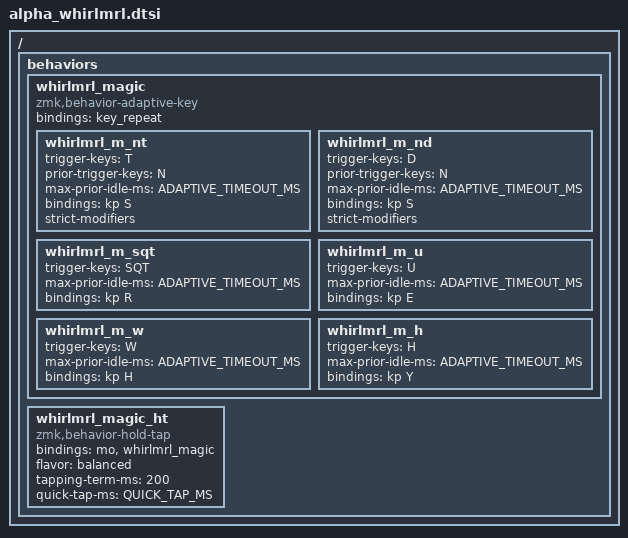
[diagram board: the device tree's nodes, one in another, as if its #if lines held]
/* Whirl-MRL — left-hand space, right-thumb repeat-magic. Inactive by default. */

/* >>> generated adaptive swaps (do not edit — run ./scripts/generate) >>> */
#include "../generated/alpha_whirlmrl.dtsi"
/* <<< end generated adaptive swaps <<< */

/* Repeat-magic thumb (hand-written; not a two-letter swap). */
#if WHIRLMRL_ADAPTIVE
ZMK_ADAPTIVE_KEY(whirlmrl_magic, bindings = <&key_repeat>;
    whirlmrl_m_nt  { trigger-keys = <T>; prior-trigger-keys = <N>; max-prior-idle-ms = <ADAPTIVE_TIMEOUT_MS>; bindings = <&kp S>; strict-modifiers; };
    whirlmrl_m_nd  { trigger-keys = <D>; prior-trigger-keys = <N>; max-prior-idle-ms = <ADAPTIVE_TIMEOUT_MS>; bindings = <&kp S>; strict-modifiers; };
    whirlmrl_m_sqt { trigger-keys = <SQT>; max-prior-idle-ms = <ADAPTIVE_TIMEOUT_MS>; bindings = <&kp R>; };
    whirlmrl_m_u   { trigger-keys = <U>;   max-prior-idle-ms = <ADAPTIVE_TIMEOUT_MS>; bindings = <&kp E>; };
    whirlmrl_m_w   { trigger-keys = <W>;   max-prior-idle-ms = <ADAPTIVE_TIMEOUT_MS>; bindings = <&kp H>; };
    whirlmrl_m_h   { trigger-keys = <H>;   max-prior-idle-ms = <ADAPTIVE_TIMEOUT_MS>; bindings = <&kp Y>; };
)
ZMK_HOLD_TAP(whirlmrl_magic_ht, bindings = <&mo>, <&whirlmrl_magic>;
             flavor = "balanced"; tapping-term-ms = <200>;
             quick-tap-ms = <QUICK_TAP_MS>;)
#define WHIRLMRL_MAGIC &whirlmrl_magic_ht LAYER_Num 0
#endif

#ifndef WHIRLMRL_C
#define WHIRLMRL_C &kp C
#endif
#ifndef WHIRLMRL_D
#define WHIRLMRL_D &kp D
#endif
#ifndef WHIRLMRL_F
#define WHIRLMRL_F &kp F
#endif
#ifndef WHIRLMRL_G
#define WHIRLMRL_G &kp G
#endif
#ifndef WHIRLMRL_H
#define WHIRLMRL_H &hml LSHFT H
#endif
#ifndef WHIRLMRL_L
#define WHIRLMRL_L &kp L
#endif
#ifndef WHIRLMRL_M
#define WHIRLMRL_M &kp M
#endif
#ifndef WHIRLMRL_P
#define WHIRLMRL_P &kp P
#endif
#ifndef WHIRLMRL_S
#define WHIRLMRL_S &hml LALT S
#endif
#ifndef WHIRLMRL_T
#define WHIRLMRL_T &hml LCTRL T
#endif
#ifndef WHIRLMRL_W
#define WHIRLMRL_W &kp W
#endif
#ifndef WHIRLMRL_MAGIC
#define WHIRLMRL_MAGIC &num_repeat LAYER_Num 0
#endif

ZMK_BASE_LAYER(WhirlMrl,
//╭──────────┬──────────┬──────────┬──────────┬──────────╮   ╭──────────┬──────────┬──────────┬──────────┬──────────╮
    &kp B      WHIRLMRL_C WHIRLMRL_D WHIRLMRL_W &kp K      ,  &sqt_dqt   WHIRLMRL_L &kp U      &kp O      &kp J      ,
//├──────────┼──────────┼──────────┼──────────┼──────────┤   ├──────────┼──────────┼──────────┼──────────┼──────────┤
   &hml LGUI N WHIRLMRL_S WHIRLMRL_T WHIRLMRL_H &kp Y , WHIRLMRL_M &hmr RSHFT R &hmr RCTRL E &hmr RALT A &hmr RGUI I ,
//├──────────┼──────────┼──────────┼──────────┼──────────┤   ├──────────┼──────────┼──────────┼──────────┼──────────┤
    &kp Q      WHIRLMRL_G WHIRLMRL_P WHIRLMRL_F &kp V      ,  &kp Z      &kp X      &dot_qmark &minus_slash &comma_excl ,
//╰──────────┴──────────┴──────────┼──────────┼──────────┤   ├──────────┼──────────┼──────────┴──────────┴──────────╯
        LH_NONE &thumb_bspc LAYER_Nav 0  &thumb_spc LAYER_Symbol SPACE , WHIRLMRL_MAGIC  &sk LSHFT RH_NONE
//                                 ╰──────────┴──────────╯   ╰──────────┴──────────╯
)
